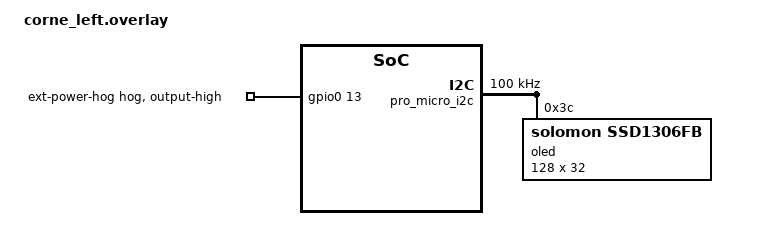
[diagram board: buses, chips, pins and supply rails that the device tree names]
&gpio0 {
    status = "okay";
    ext-power-hog {
        gpio-hog;
        gpios = <13 GPIO_ACTIVE_HIGH>;
        output-high;
    };
};

&pro_micro_i2c {
    compatible = "nordic,nrf-twim";
    status = "okay";
    clock-frequency = <I2C_BITRATE_STANDARD>;
    zephyr,concat-buf-size = <2048>;

    oled: ssd1306@3c {
        compatible = "solomon,ssd1306fb";
        reg = <0x3c>;
        width = <128>;
        height = <32>;
        segment-offset = <0>;
        page-offset = <0>;
        display-offset = <0>;
        multiplex-ratio = <31>;
        segment-remap;
        com-invdir;
        com-sequential;
        prechargep = <0x22>;
    };
};

/ {
    chosen {
        zephyr,display = &oled;
    };
};
